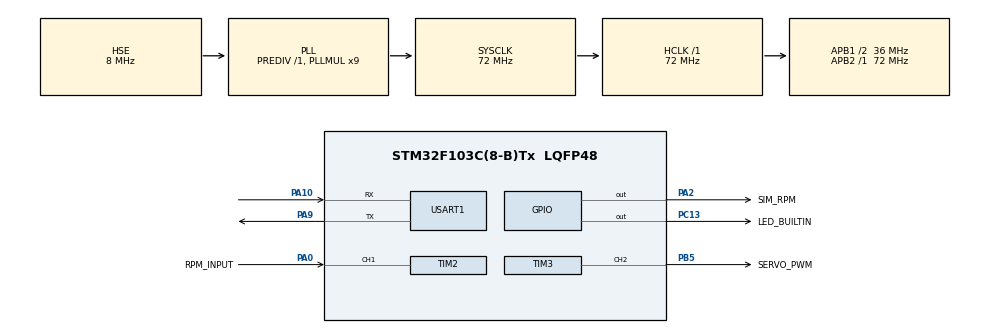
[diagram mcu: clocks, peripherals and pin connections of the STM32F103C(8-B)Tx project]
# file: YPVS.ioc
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Mcu.Family=STM32F1
RCC.PLLSourceVirtual=RCC_PLLSOURCE_HSE
NVIC.DMA1_Channel5_IRQn=true\:1\:0\:true\:true\:true\:4\:false\:true
PD1-OSC_OUT.Mode=HSE-External-Oscillator
Dma.USART1_RX.0.PeriphDataAlignment=DMA_PDATAALIGN_BYTE
TIM2.CounterMode=TIM_COUNTERMODE_UP
PA10.Mode=Asynchronous
TIM1.Channel-Output\ Compare1\ No\ Output=TIM_CHANNEL_1
PA2.GPIO_Speed=GPIO_SPEED_FREQ_MEDIUM
PC13-TAMPER-RTC.Signal=GPIO_Output
NVIC.TIM1_UP_IRQn=true\:1\:1\:true\:true\:true\:3\:true\:true
PD0-OSC_IN.Signal=RCC_OSC_IN
TIM2.ICFilter_2=15
RCC.APB1CLKDivider=RCC_HCLK_DIV2
RCC.SYSCLKSource=RCC_SYSCLKSOURCE_PLLCLK
ProjectManager.StackSize=0x400
PA0-WKUP.GPIO_Label=RPM_INPUT
PA0-WKUP.Signal=S_TIM2_CH1_ETR
VP_TIM1_VS_no_output1.Mode=Output Compare1 No Output
PD1-OSC_OUT.Signal=RCC_OSC_OUT
RCC.ADCPresc=RCC_ADCPCLK2_DIV6
PA13.Signal=SYS_JTMS-SWDIO
PA9.Mode=Asynchronous
TIM1.Prescaler=71
ProjectManager.TargetToolchain=Other Toolchains (GPDSC)
Dma.USART1_RX.0.Direction=DMA_PERIPH_TO_MEMORY
RCC.HCLKFreq_Value=72000000
RCC.APB2TimFreq_Value=72000000
TIM3.Period=19999
PA9.Signal=USART1_TX
RCC.USBFreq_Value=72000000
RCC.AHBFreq_Value=72000000
Dma.USART1_RX.0.PeriphInc=DMA_PINC_DISABLE
Dma.USART1_RX.0.Priority=DMA_PRIORITY_LOW
PD0-OSC_IN.Mode=HSE-External-Oscillator
SH.S_TIM3_CH2.0=TIM3_CH2,PWM Generation2 CH2
board=custom
PC13-TAMPER-RTC.GPIO_Label=LED_BUILTIN
RCC.PLLMUL=RCC_PLL_MUL9
RCC.APB2Freq_Value=72000000
VP_TIM2_VS_ClockSourceINT.Mode=Internal
PA14.Mode=Serial_Wire
TIM3.Prescaler=71
NVIC.TIM2_IRQn=true\:1\:1\:true\:true\:true\:1\:true\:true
Dma.USART1_RX.0.MemDataAlignment=DMA_MDATAALIGN_BYTE
TIM2.Period=9999
Dma.USART1_RX.0.MemInc=DMA_MINC_ENABLE
PA13.Mode=Serial_Wire
Mcu.Name=STM32F103C(8-B)Tx
VP_TIM1_VS_ClockSourceINT.Mode=Internal
PA2.Signal=GPIO_Output
RCC.SYSCLKFreq_VALUE=72000000
Mcu.Package=LQFP48
PB5.Signal=S_TIM3_CH2
TIM2.Prescaler=719
USART1.VirtualMode=VM_ASYNC
PA2.GPIO_Label=SIM_RPM
SH.S_TIM2_CH1_ETR.0=TIM2_CH1,PWM_Input_1
PA10.Signal=USART1_RX
PA14.Signal=SYS_JTCK-SWCLK
ProjectManager.HeapSize=0x200
NVIC.PriorityGroup=NVIC_PRIORITYGROUP_3
TIM3.Channel-PWM\ Generation2\ CH2=TIM_CHANNEL_2
PB5.GPIO_Label=SERVO_PWM
RCC.APB1TimFreq_Value=72000000
PA0-WKUP.GPIO_PuPd=GPIO_PULLUP
Dma.USART1_RX.0.Mode=DMA_NORMAL
TIM1.Period=4999
NVIC.USART1_IRQn=true\:1\:0\:true\:true\:true\:2\:true\:true
Dma.Request0=USART1_RX
RCC.APB1Freq_Value=36000000
Dma.USART1_RX.0.Instance=DMA1_Channel5
VP_TIM3_VS_ClockSourceINT.Mode=Internal

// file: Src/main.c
/* USER CODE BEGIN Header */
/**
  ******************************************************************************
  * @file           : main.c
  * @brief          : Main program body
  ******************************************************************************
  * @attention
  *
  * <h2><center>&copy; Copyright (c) 2020 STMicroelectronics.
  * All rights reserved.</center></h2>
  *
  * This software component is licensed by ST under BSD 3-Clause license,
  * the "License"; You may not use this file except in compliance with the
  * License. You may obtain a copy of the License at:
  *                        opensource.org/licenses/BSD-3-Clause
  *
  ******************************************************************************
  */
/* USER CODE END Header */
#include "main.h"
#include "dma.h"
#include "tim.h"
#include "usart.h"
#include "gpio.h"

/* USER CODE BEGIN Includes */
#include "app.h"
#include "framework.h"
/* USER CODE END Includes */

void SystemClock_Config(void);
static void MX_NVIC_Init(void);

int main(void)
{

  /* MCU Configuration--------------------------------------------------------*/

  /* Reset of all peripherals, Initializes the Flash interface and the Systick. */
  HAL_Init();

  /* Configure the system clock */
  SystemClock_Config();

  /* Initialize all configured peripherals */
  MX_GPIO_Init();
  MX_DMA_Init();
  MX_TIM2_Init();
  MX_TIM3_Init();
  MX_USART1_UART_Init();
  MX_TIM1_Init();

  /* Initialize interrupts */
  MX_NVIC_Init();
  /* USER CODE BEGIN 2 */
  initPeripherals();
  /* USER CODE END 2 */

  /* Infinite loop */
  /* USER CODE BEGIN WHILE */
  while (1){
    mainLoop();
    /* USER CODE END WHILE */

  }
}

void SystemClock_Config(void)
{
  RCC_OscInitTypeDef RCC_OscInitStruct = {0};
  RCC_ClkInitTypeDef RCC_ClkInitStruct = {0};

  /** Initializes the RCC Oscillators according to the specified parameters
  * in the RCC_OscInitTypeDef structure.
  */
  RCC_OscInitStruct.OscillatorType = RCC_OSCILLATORTYPE_HSE;
  RCC_OscInitStruct.HSEState = RCC_HSE_ON;
  RCC_OscInitStruct.HSEPredivValue = RCC_HSE_PREDIV_DIV1;
  RCC_OscInitStruct.HSIState = RCC_HSI_ON;
  RCC_OscInitStruct.PLL.PLLState = RCC_PLL_ON;
  RCC_OscInitStruct.PLL.PLLSource = RCC_PLLSOURCE_HSE;
  RCC_OscInitStruct.PLL.PLLMUL = RCC_PLL_MUL9;
  if (HAL_RCC_OscConfig(&RCC_OscInitStruct) != HAL_OK)
  {
    Error_Handler();
  }
  /** Initializes the CPU, AHB and APB buses clocks
  */
  RCC_ClkInitStruct.ClockType = RCC_CLOCKTYPE_HCLK|RCC_CLOCKTYPE_SYSCLK
                              |RCC_CLOCKTYPE_PCLK1|RCC_CLOCKTYPE_PCLK2;
  RCC_ClkInitStruct.SYSCLKSource = RCC_SYSCLKSOURCE_PLLCLK;
  RCC_ClkInitStruct.AHBCLKDivider = RCC_SYSCLK_DIV1;
  RCC_ClkInitStruct.APB1CLKDivider = RCC_HCLK_DIV2;
  RCC_ClkInitStruct.APB2CLKDivider = RCC_HCLK_DIV1;

  if (HAL_RCC_ClockConfig(&RCC_ClkInitStruct, FLASH_LATENCY_2) != HAL_OK)
  {
    Error_Handler();
  }
}

/**
  * @brief NVIC Configuration.
  * @retval None
  */
static void MX_NVIC_Init(void)
{
  /* TIM2_IRQn interrupt configuration */
  HAL_NVIC_SetPriority(TIM2_IRQn, 1, 1);
  HAL_NVIC_EnableIRQ(TIM2_IRQn);
  /* USART1_IRQn interrupt configuration */
  HAL_NVIC_SetPriority(USART1_IRQn, 1, 0);
  HAL_NVIC_EnableIRQ(USART1_IRQn);
  /* TIM1_UP_IRQn interrupt configuration */
  HAL_NVIC_SetPriority(TIM1_UP_IRQn, 1, 1);
  HAL_NVIC_EnableIRQ(TIM1_UP_IRQn);
  /* DMA1_Channel5_IRQn interrupt configuration */
  HAL_NVIC_SetPriority(DMA1_Channel5_IRQn, 1, 0);
  HAL_NVIC_EnableIRQ(DMA1_Channel5_IRQn);
}

/* USER CODE BEGIN 4 */

void HAL_TIM_IC_CaptureCallback(TIM_HandleTypeDef *htim){
  handle_TIM_IC_interrupts(htim);
}

void HAL_TIM_PeriodElapsedCallback(TIM_HandleTypeDef* htim){
  handle_TIM_PeriodElapsed_interrupts(htim);
}

/* USER CODE END 4 */

void Error_Handler(void)
{
}

/************************ (C) COPYRIGHT STMicroelectronics *****END OF FILE****/
